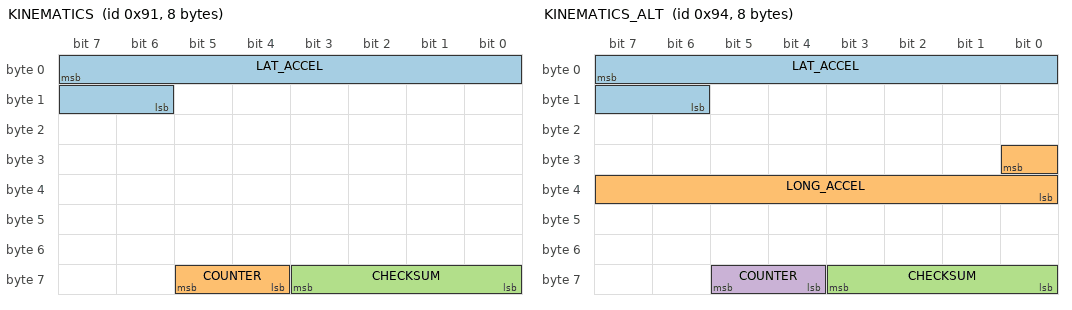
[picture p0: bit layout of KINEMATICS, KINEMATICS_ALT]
BO_ 145 KINEMATICS: 8 XXX
 SG_ LAT_ACCEL : 7|10@0+ (0.02,-512) [-20|20] "m/s2" EON
 SG_ COUNTER : 61|2@0+ (1,0) [0|3] "" EON
 SG_ CHECKSUM : 59|4@0+ (1,0) [0|3] "" EON

BO_ 148 KINEMATICS_ALT: 8 XXX
 SG_ LAT_ACCEL : 7|10@0+ (0.02,-512) [-20|20] "m/s2" EON
 SG_ LONG_ACCEL : 24|9@0- (-0.02,0) [-20|20] "m/s2" EON
 SG_ CHECKSUM : 59|4@0+ (1,0) [0|3] "" EON
 SG_ COUNTER : 61|2@0+ (1,0) [0|3] "" EON

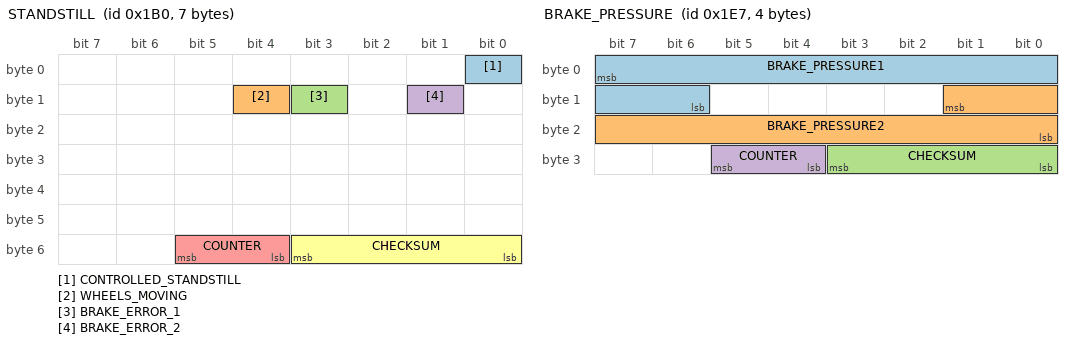
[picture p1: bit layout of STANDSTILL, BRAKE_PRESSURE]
BO_ 432 STANDSTILL: 7 VSA
 SG_ CONTROLLED_STANDSTILL : 0|1@0+ (1,0) [0|1] "" EON
 SG_ WHEELS_MOVING : 12|1@0+ (1,0) [0|1] "" EON
 SG_ BRAKE_ERROR_1 : 11|1@0+ (1,0) [0|1] "" EON
 SG_ BRAKE_ERROR_2 : 9|1@0+ (1,0) [0|1] "" EON
 SG_ COUNTER : 53|2@0+ (1,0) [0|3] "" EON
 SG_ CHECKSUM : 51|4@0+ (1,0) [0|3] "" EON

BO_ 487 BRAKE_PRESSURE: 4 VSA
 SG_ BRAKE_PRESSURE1 : 7|10@0+ (0.015625,-103) [0|1000] "" EON
 SG_ BRAKE_PRESSURE2 : 9|10@0+ (0.015625,-103) [0|1000] "" EON
 SG_ CHECKSUM : 27|4@0+ (1,0) [0|15] "" EON
 SG_ COUNTER : 29|2@0+ (1,0) [0|3] "" EON

BO_ 506 BRAKE_COMMAND: 8 ADAS
 SG_ COMPUTER_BRAKE : 7|10@0+ (1,0) [0|1] "" EBCM
 SG_ BRAKE_PUMP_REQUEST : 8|1@0+ (1,0) [0|1] "" EBCM
 SG_ BRAKE_PUMP_REQUEST_HYBRID : 11|1@0+ (1,0) [0|1] "" EBCM
 SG_ SET_ME_X00 : 23|3@0+ (1,0) [0|1] "" EBCM
 SG_ CRUISE_OVERRIDE : 20|1@0+ (1,0) [0|1] "" EBCM
 SG_ SET_ME_X00_2 : 19|1@0+ (1,0) [0|1] "" EBCM
 SG_ CRUISE_FAULT_CMD : 18|1@0+ (1,0) [0|1] "" EBCM
 SG_ CRUISE_CANCEL_CMD : 17|1@0+ (1,0) [0|1] "" EBCM
 SG_ COMPUTER_BRAKE_REQUEST : 16|1@0+ (1,0) [0|1] "" EBCM
 SG_ SET_ME_1 : 31|1@0+ (1,0) [0|1] "" EBCM
 SG_ AEB_REQ_1 : 29|1@0+ (1,0) [0|1] "" XXX
 SG_ AEB_REQ_2 : 26|3@0+ (1,0) [0|7] "" XXX
 SG_ BRAKE_LIGHTS : 39|1@0+ (1,0) [0|1] "" EBCM
 SG_ CRUISE_STATES : 38|7@0+ (1,0) [0|1] "" EBCM
 SG_ CHIME : 47|3@0+ (1,0) [0|7] "" EBCM
 SG_ SET_ME_X00_3 : 44|1@0+ (1,0) [0|1] "" EBCM
 SG_ FCW : 43|2@0+ (1,0) [0|3] "" EBCM
 SG_ AEB_STATUS : 41|2@0+ (1,0) [0|3] "" XXX
 SG_ COMPUTER_BRAKE_HYBRID : 55|10@0+ (1,0) [0|0] "" EBCM
 SG_ COUNTER : 61|2@0+ (1,0) [0|3] "" EBCM
 SG_ CHECKSUM : 59|4@0+ (1,0) [0|15] "" EBCM

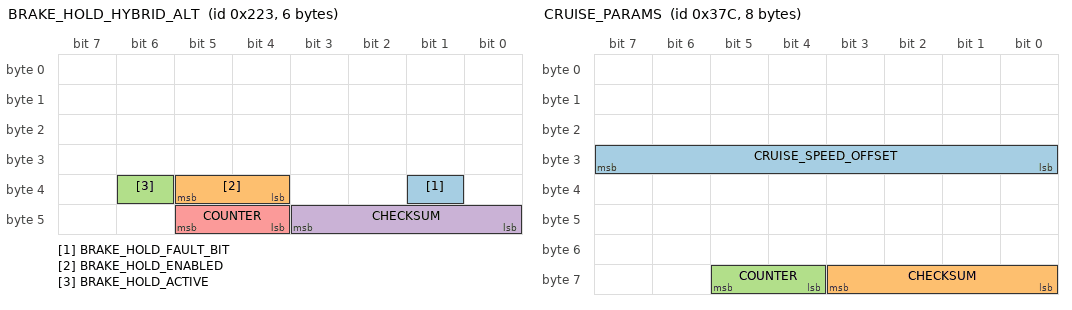
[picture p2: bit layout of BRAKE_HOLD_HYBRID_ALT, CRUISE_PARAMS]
BO_ 547 BRAKE_HOLD_HYBRID_ALT: 6 XXX
 SG_ BRAKE_HOLD_FAULT_BIT : 33|1@0+ (1,0) [0|1] "" XXX
 SG_ BRAKE_HOLD_ENABLED : 37|2@0+ (1,0) [0|7] "" XXX
 SG_ BRAKE_HOLD_ACTIVE : 38|1@0+ (1,0) [0|1] "" XXX
 SG_ CHECKSUM : 43|4@0+ (1,0) [0|15] "" XXX
 SG_ COUNTER : 45|2@0+ (1,0) [0|3] "" XXX

BO_ 892 CRUISE_PARAMS: 8 PCM
 SG_ CRUISE_SPEED_OFFSET : 31|8@0- (0.1,0) [-128|127] "kph" EON
 SG_ CHECKSUM : 59|4@0+ (1,0) [0|3] "" EON
 SG_ COUNTER : 61|2@0+ (1,0) [0|3] "" EON

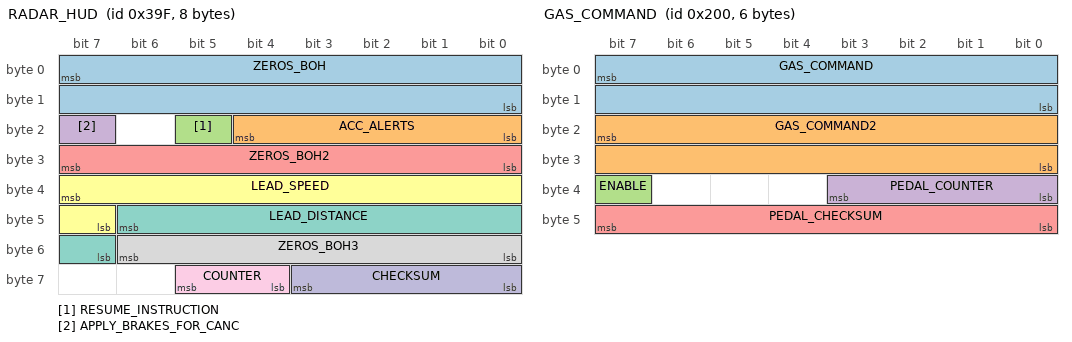
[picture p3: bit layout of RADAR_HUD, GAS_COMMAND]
BO_ 927 RADAR_HUD: 8 ADAS
 SG_ ZEROS_BOH : 7|16@0+ (1,0) [0|127] "" BDY
 SG_ ACC_ALERTS : 20|5@0+ (1,0) [0|15] "" BDY
 SG_ RESUME_INSTRUCTION : 21|1@0+ (1,0) [0|15] "" BDY
 SG_ APPLY_BRAKES_FOR_CANC : 23|1@0+ (1,0) [0|15] "" BDY
 SG_ ZEROS_BOH2 : 31|8@0+ (1,0) [0|127] "" BDY
 SG_ LEAD_SPEED : 39|9@0+ (1,0) [0|127] "" BDY
 SG_ LEAD_DISTANCE : 46|8@0+ (1,0) [0|31] "" BDY
 SG_ ZEROS_BOH3 : 54|7@0+ (1,0) [0|127] "" BDY
 SG_ COUNTER : 61|2@0+ (1,0) [0|3] "" BDY
 SG_ CHECKSUM : 59|4@0+ (1,0) [0|15] "" BDY

CM_ SG_ 506 AEB_REQ_1 "set for duration of suspected AEB event";
CM_ SG_ 506 COMPUTER_BRAKE_ALT "Used by dual-can Nidec";
CM_ SG_ 506 BRAKE_PUMP_REQUEST_ALT "Used by dual-can Nidec";

VAL_ 506 FCW 3 "fcw" 2 "fcw" 1 "fcw" 0 "no_fcw";
VAL_ 506 CHIME 4 "double_chime" 3 "single_chime" 2 "continuous_chime" 1 "repeating_chime" 0 "no_chime";
VAL_ 506 AEB_STATUS 3 "aeb_prepare" 2 "aeb_ready" 1 "aeb_braking" 0 "no_aeb";
VAL_ 927 ACC_ALERTS 29 "esp_active_acc_canceled" 10 "b_pedal_applied" 9 "speed_too_low" 8 "speed_too_high" 7 "p_brake_applied" 6 "gear_no_d" 5 "seatbelt" 4 "too_steep_downhill" 3 "too_steep_uphill" 2 "too_close" 1 "no_vehicle_ahead" ;
VAL_ 927 LEAD_DISTANCE 254 "no lead";
VAL_ 927 LEAD_SPEED 510 "no lead";

CM  --  adding community gas interceptor below --

BO_ 512 GAS_COMMAND: 6 EON
 SG_ GAS_COMMAND : 7|16@0+ (0.253984064,-83.3) [0|1] "" INTERCEPTOR
 SG_ GAS_COMMAND2 : 23|16@0+ (0.126992032,-83.3) [0|1] "" INTERCEPTOR
 SG_ ENABLE : 39|1@0+ (1,0) [0|1] "" INTERCEPTOR
 SG_ PEDAL_COUNTER : 35|4@0+ (1,0) [0|15] "" INTERCEPTOR
 SG_ PEDAL_CHECKSUM : 47|8@0+ (1,0) [0|255] "" INTERCEPTOR

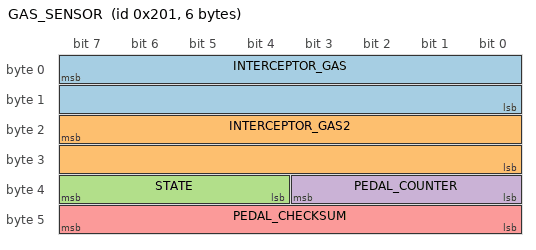
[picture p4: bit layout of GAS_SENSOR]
BO_ 513 GAS_SENSOR: 6 INTERCEPTOR
 SG_ INTERCEPTOR_GAS : 7|16@0+ (1,0) [0|1] "" EON
 SG_ INTERCEPTOR_GAS2 : 23|16@0+ (1,0) [0|1] "" EON
 SG_ STATE : 39|4@0+ (1,0) [0|15] "" EON
 SG_ PEDAL_COUNTER : 35|4@0+ (1,0) [0|15] "" EON
 SG_ PEDAL_CHECKSUM : 47|8@0+ (1,0) [0|255] "" EON

VAL_ 513 STATE 5 "FAULT_TIMEOUT" 4 "FAULT_STARTUP" 3 "FAULT_SCE" 2 "FAULT_SEND" 1 "FAULT_BAD_CHECKSUM" 0 "NO_FAULT" ;
